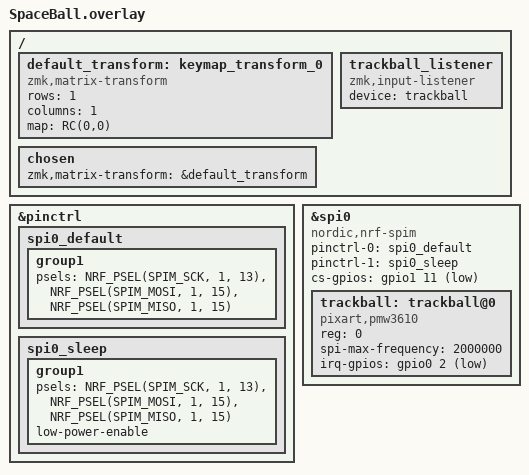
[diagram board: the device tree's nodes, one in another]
#include <dt-bindings/zmk/matrix_transform.h>

/ {
    default_transform: keymap_transform_0 {
        compatible = "zmk,matrix-transform";
        rows = <1>;
        columns = <1>;
        map = <RC(0,0)>;
    };

    chosen {
        zmk,matrix-transform = &default_transform;
    };
};

&pinctrl {
    spi0_default: spi0_default {
        group1 {
            psels = <NRF_PSEL(SPIM_SCK, 1, 13)>,
                    <NRF_PSEL(SPIM_MOSI, 1, 15)>,
                    <NRF_PSEL(SPIM_MISO, 1, 15)>;
        };
    };

    spi0_sleep: spi0_sleep {
        group1 {
            psels = <NRF_PSEL(SPIM_SCK, 1, 13)>,
                    <NRF_PSEL(SPIM_MOSI, 1, 15)>,
                    <NRF_PSEL(SPIM_MISO, 1, 15)>;
            low-power-enable;
        };
    };
};

&spi0 {
    status = "okay";
    compatible = "nordic,nrf-spim";

    pinctrl-0 = <&spi0_default>;
    pinctrl-1 = <&spi0_sleep>;
    pinctrl-names = "default", "sleep";

    /*
     * SpaceBall schematic:
     *   NCS  -> XIAO D6  -> P1.11
     *   SCLK -> XIAO D8  -> P1.13
     *   SDIO -> XIAO D10 -> P1.15
     */
    cs-gpios = <&gpio1 11 GPIO_ACTIVE_LOW>;

    trackball: trackball@0 {
        status = "okay";
        compatible = "pixart,pmw3610";
        reg = <0>;
        spi-max-frequency = <2000000>;

        /* IRQ -> XIAO D0 -> P0.02 */
        irq-gpios = <&gpio0 2 (GPIO_ACTIVE_LOW | GPIO_PULL_UP)>;
    };
};

/ {
    trackball_listener: trackball_listener {
        compatible = "zmk,input-listener";
        device = <&trackball>;
        status = "okay";
    };
};
